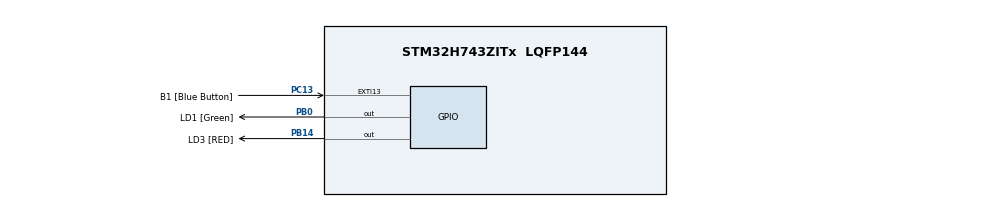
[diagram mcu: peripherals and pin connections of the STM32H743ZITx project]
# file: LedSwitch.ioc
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CORTEX_M7.CPU_DCache=Enabled
CORTEX_M7.CPU_ICache=Enabled
Mcu.Family=STM32H7
Mcu.Name=STM32H743ZITx
Mcu.Package=LQFP144
NVIC.EXTI15_10_IRQn=true\:0\:0\:false\:true\:true\:1\:true\:true
NVIC.PriorityGroup=NVIC_PRIORITYGROUP_4
PB0.GPIO_Label=LD1 [Green]
PB0.Signal=GPIO_Output
PB14.GPIO_Label=LD3 [RED]
PB14.Signal=GPIO_Output
PC13.GPIO_Label=B1 [Blue Button]
PC13.GPIO_ModeDefaultEXTI=GPIO_MODE_IT_RISING
PC13.Signal=GPXTI13
ProjectManager.HeapSize=0x200
ProjectManager.StackSize=0x400
ProjectManager.TargetToolchain=STM32CubeIDE
RCC.ADCFreq_Value=129000000
RCC.APB1Freq_Value=64000000
RCC.APB2Freq_Value=64000000
RCC.APB3Freq_Value=64000000
RCC.APB4Freq_Value=64000000
RCC.CortexFreq_Value=64000000
RCC.HCLKFreq_Value=64000000
RCC.SYSCLKFreq_VALUE=64000000
RCC.USBFreq_Value=129000000
board=NUCLEO-H743ZI2

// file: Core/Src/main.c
/* USER CODE BEGIN Header */
/**
  ******************************************************************************
  * @file           : main.c
  * @brief          : Main program body
  ******************************************************************************
  * @attention
  *
  * <h2><center>&copy; Copyright (c) 2019 STMicroelectronics.
  * All rights reserved.</center></h2>
  *
  * This software component is licensed by ST under BSD 3-Clause license,
  * the "License"; You may not use this file except in compliance with the
  * License. You may obtain a copy of the License at:
  *                        opensource.org/licenses/BSD-3-Clause
  *
  ******************************************************************************
  */
/* USER CODE END Header */

#include "main.h"

/* USER CODE BEGIN PV */
__IO uint32_t ButtonState = 0;
/* USER CODE END PV */

void SystemClock_Config(void);
static void MX_GPIO_Init(void);
static void MX_NVIC_Init(void);

int main(void)
{

  /* Enable I-Cache---------------------------------------------------------*/
  SCB_EnableICache();

  /* Enable D-Cache---------------------------------------------------------*/
  SCB_EnableDCache();

  /* MCU Configuration--------------------------------------------------------*/

  /* Reset of all peripherals, Initializes the Flash interface and the Systick. */
  HAL_Init();

  /* Configure the system clock */
  SystemClock_Config();

  /* Initialize all configured peripherals */
  MX_GPIO_Init();

  /* Initialize interrupts */
  MX_NVIC_Init();

  /* Infinite loop */
  while (1)
  {

    /* USER CODE BEGIN 3 */
    if(ButtonState != 0)
	{
  	  ButtonState = 0;
	  HAL_GPIO_TogglePin(LD1_GPIO_Port, LD1_Pin);
	  HAL_GPIO_TogglePin(LD3_GPIO_Port, LD3_Pin);
	  HAL_Delay(5);
	}
  }
  /* USER CODE END 3 */
}

void SystemClock_Config(void)
{
  RCC_OscInitTypeDef RCC_OscInitStruct = {0};
  RCC_ClkInitTypeDef RCC_ClkInitStruct = {0};

  /** Supply configuration update enable
  */
  HAL_PWREx_ConfigSupply(PWR_LDO_SUPPLY);
  /** Configure the main internal regulator output voltage
  */
  __HAL_PWR_VOLTAGESCALING_CONFIG(PWR_REGULATOR_VOLTAGE_SCALE3);

  while(!__HAL_PWR_GET_FLAG(PWR_FLAG_VOSRDY)) {}
  /** Initializes the CPU, AHB and APB busses clocks
  */
  RCC_OscInitStruct.OscillatorType = RCC_OSCILLATORTYPE_HSI;
  RCC_OscInitStruct.HSIState = RCC_HSI_DIV1;
  RCC_OscInitStruct.HSICalibrationValue = RCC_HSICALIBRATION_DEFAULT;
  RCC_OscInitStruct.PLL.PLLState = RCC_PLL_NONE;
  if (HAL_RCC_OscConfig(&RCC_OscInitStruct) != HAL_OK)
  {
    Error_Handler();
  }
  /** Initializes the CPU, AHB and APB busses clocks
  */
  RCC_ClkInitStruct.ClockType = RCC_CLOCKTYPE_HCLK|RCC_CLOCKTYPE_SYSCLK
                              |RCC_CLOCKTYPE_PCLK1|RCC_CLOCKTYPE_PCLK2
                              |RCC_CLOCKTYPE_D3PCLK1|RCC_CLOCKTYPE_D1PCLK1;
  RCC_ClkInitStruct.SYSCLKSource = RCC_SYSCLKSOURCE_HSI;
  RCC_ClkInitStruct.SYSCLKDivider = RCC_SYSCLK_DIV1;
  RCC_ClkInitStruct.AHBCLKDivider = RCC_HCLK_DIV1;
  RCC_ClkInitStruct.APB3CLKDivider = RCC_APB3_DIV1;
  RCC_ClkInitStruct.APB1CLKDivider = RCC_APB1_DIV1;
  RCC_ClkInitStruct.APB2CLKDivider = RCC_APB2_DIV1;
  RCC_ClkInitStruct.APB4CLKDivider = RCC_APB4_DIV1;

  if (HAL_RCC_ClockConfig(&RCC_ClkInitStruct, FLASH_LATENCY_0) != HAL_OK)
  {
    Error_Handler();
  }
}

/**
  * @brief NVIC Configuration.
  * @retval None
  */
static void MX_NVIC_Init(void)
{
  /* EXTI15_10_IRQn interrupt configuration */
  HAL_NVIC_SetPriority(B1_EXTI_IRQn, 0, 0);
  HAL_NVIC_EnableIRQ(B1_EXTI_IRQn);
}

static void MX_GPIO_Init(void)
{
  GPIO_InitTypeDef GPIO_InitStruct = {0};

  /* GPIO Ports Clock Enable */
  __HAL_RCC_GPIOC_CLK_ENABLE();
  __HAL_RCC_GPIOB_CLK_ENABLE();

  /*Configure GPIO pin Output Level */
  HAL_GPIO_WritePin(LD1_GPIO_Port, LD1_Pin, GPIO_PIN_RESET);
  HAL_GPIO_WritePin(LD1_GPIO_Port, LD3_Pin, GPIO_PIN_SET);

  /*Configure GPIO pin : B1_Pin */
  GPIO_InitStruct.Pin = B1_Pin;
  GPIO_InitStruct.Mode = GPIO_MODE_IT_RISING;
  GPIO_InitStruct.Pull = GPIO_NOPULL;
  HAL_GPIO_Init(B1_GPIO_Port, &GPIO_InitStruct);

  /*Configure GPIO pins : LD1_Pin LD3_Pin */
  GPIO_InitStruct.Pin = LD1_Pin|LD3_Pin;
  GPIO_InitStruct.Mode = GPIO_MODE_OUTPUT_PP;
  GPIO_InitStruct.Pull = GPIO_NOPULL;
  GPIO_InitStruct.Speed = GPIO_SPEED_FREQ_LOW;
  HAL_GPIO_Init(LD1_GPIO_Port, &GPIO_InitStruct);

}

/* USER CODE BEGIN 4 */
/**
  * @brief EXTI line detection callbacks
  * @param GPIO_Pin: Specifies the pins connected EXTI line
  * @retval None
  */
void HAL_GPIO_EXTI_Callback(uint16_t GPIO_Pin)
{
  if (GPIO_Pin == B1_Pin)
  {
    ButtonState = 1;
  }
}
/* USER CODE END 4 */

void Error_Handler(void)
{
}

/************************ (C) COPYRIGHT STMicroelectronics *****END OF FILE****/
